# STM32G544 register map
File version: 2.0.0
CPU: CM33 r0p4, little endian, MPU, FPU, 4 interrupt priority bits
Registers are 32-bit, read-write, reset 0x0 unless marked. A register's access mark holds for its fields unless they carry their own. Offsets are from the block's base; [hi:lo] are bit positions; {n}, {i} and the like mark numbered series; 'fields as' and 'values as' point back to an identical list.

## GPDMA1 — GPDMA register block
Base 0x40020000
Same registers: GPDMA2 0x40021000, GPDMA1_S 0x50020000, GPDMA2_S 0x50021000
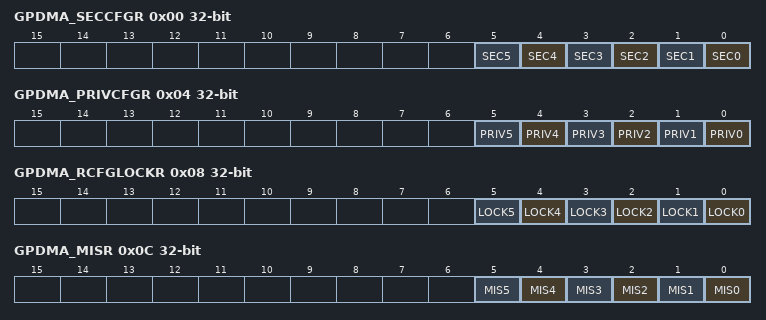
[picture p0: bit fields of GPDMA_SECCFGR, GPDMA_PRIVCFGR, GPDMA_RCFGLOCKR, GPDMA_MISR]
0x00 GPDMA_SECCFGR — GPDMA secure configuration register
  [all] fields
    0=Nonsecure; 1=Secure
  [n] SEC{n} (n=0..5) — secure state of channel x
0x04 GPDMA_PRIVCFGR — GPDMA privileged configuration register
  [all] fields
    0=unprivileged; 1=privileged
  [n] PRIV{n} (n=0..5) — privileged state of channel x
0x08 GPDMA_RCFGLOCKR — GPDMA configuration lock register
  [all] fields
    0=secure privilege configuration of the channel x is writable; 1=secure privilege configuration of the channel x is not writable
  [n] LOCK{n} (n=0..5) — lock the configuration of GPDMA_SECCFGR.
0x0C GPDMA_MISR ro — GPDMA nonsecure masked interrupt status register
  [all] fields
    0=no interrupt occurred on channel x; 1=an interrupt occurred on channel x
  [n] MIS{n} (n=0..5) — masked interrupt status of channel x
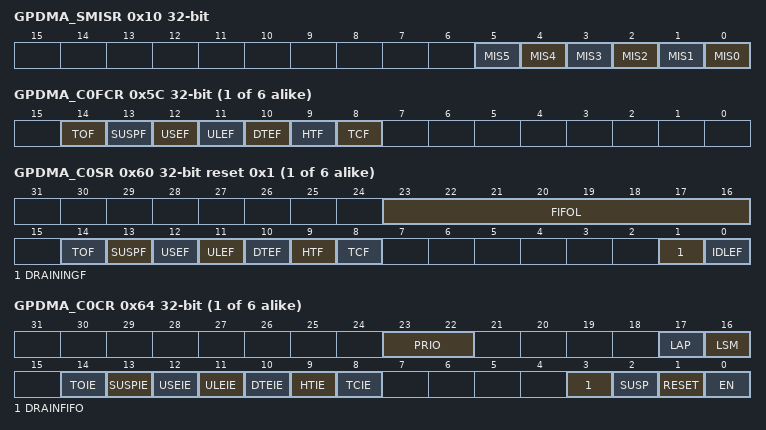
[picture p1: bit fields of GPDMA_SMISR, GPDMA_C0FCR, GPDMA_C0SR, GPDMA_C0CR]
0x10 GPDMA_SMISR ro — GPDMA secure masked interrupt status register
  [all] fields
    0=no interrupt occurred on the secure channel x; 1=an interrupt occurred on the secure channel x
  [n] MIS{n} (n=0..5) — masked interrupt status of the secure channel x
{0x50+0x80*i} GPDMA_C{i}LBAR (i=0..5) — GPDMA channel {i} linked-list base address register
  [31:16] LBA — linked-list base address of GPDMA channel x
{0x5C+0x80*i} GPDMA_C{i}FCR wo (i=0..5) — GPDMA channel {i} flag clear register
  [14] TOF — trigger overrun flag clear
    0=no effect; 1=corresponding TOF flag cleared
  [13] SUSPF — completed suspension flag clear
    0=no effect; 1=corresponding SUSPF flag cleared
  [12] USEF — user setting error flag clear
    0=no effect; 1=corresponding USEF flag cleared
  [11] ULEF — update link transfer error flag clear
    0=no effect; 1=corresponding ULEF flag cleared
  [10] DTEF — data transfer error flag clear
    0=no effect; 1=corresponding DTEF flag cleared
  [9] HTF — half transfer flag clear
    0=no effect; 1=corresponding HTF flag cleared
  [8] TCF — transfer complete flag clear
    0=no effect; 1=corresponding TCF flag cleared
{0x60+0x80*i} GPDMA_C{i}SR ro reset 0x1 (i=0..5) — GPDMA channel {i} status register
  [23:16] FIFOL — monitored FIFO level (in bytes)
  [14] TOF — trigger overrun flag
    0=no trigger overrun event; 1=a trigger overrun event occurred
  [13] SUSPF — completed suspension flag
    0=no completed suspension event; 1=a completed suspension event occurred
  [12] USEF — user setting error flag
    0=no user setting error event; 1=a user setting error event occurred
  [11] ULEF — update link transfer error flag
    0=no update link transfer error event; 1=a master bus error event occurred while updating a linked-list register from memory
  [10] DTEF — data transfer error flag
    0=no data transfer error event; 1=a master bus error event occurred on a data transfer
  [9] HTF — half transfer flag
    0=no half transfer event; 1=a half transfer event occurred
  [8] TCF — transfer complete flag
    0=no transfer complete event; 1=a transfer complete event occurred
  [1] DRAININGF — FIFO draining flag
    0=No received order to drain the FIFO or channel FIFO draining completed; 1=Ongoing channel FIFO draining and channel termination
  [0] IDLEF — idle flag
    0=channel not in idle state; 1=channel in idle state
{0x64+0x80*i} GPDMA_C{i}CR (i=0..5) — GPDMA channel {i} control register
  [23:22] PRIO — priority level of the channel x GPDMA transfer versus others
    0=low priority, low weight; 1=low priority, mid weight; 2=low priority, high weight; 3=high priority
  [17] LAP — linked-list allocated port
    0=port 0 (AHB) allocated; 1=port 1 (AHB) allocated
  [16] LSM — Link step mode
    0=channel executed for the full linked-list and completed at the end of the last LLI (GPDMA_CxLLR = 0); 1=channel executed once for the current LLI
  [14] TOIE — trigger overrun interrupt enable
    0=interrupt disabled; 1=interrupt enabled
  [13] SUSPIE — completed suspension interrupt enable
    0=interrupt disabled; 1=interrupt enabled
  [12] USEIE — user setting error interrupt enable
    0=interrupt disabled; 1=interrupt enabled
  [11] ULEIE — update link transfer error interrupt enable
    0=interrupt disabled; 1=interrupt enabled
  [10] DTEIE — data transfer error interrupt enable
    0=interrupt disabled; 1=interrupt enabled
  [9] HTIE — half transfer complete interrupt enable
    0=interrupt disabled; 1=interrupt enabled
  [8] TCIE — transfer complete interrupt enable
    0=interrupt disabled; 1=interrupt enabled
  [3] DRAINFIFO wo — empty FIFO
    0=Write: no action; 1=Write: drain FIFO after having suspended the channel
  [2] SUSP — suspend
    0=write: resume channel, read: channel not suspended; 1=write: suspend channel, read: channel suspended
  [1] RESET wo
    0=no channel reset; 1=channel reset
  [0] EN — enable
    0=write: ignored, read: channel disabled; 1=write: enable channel, read: channel enabled
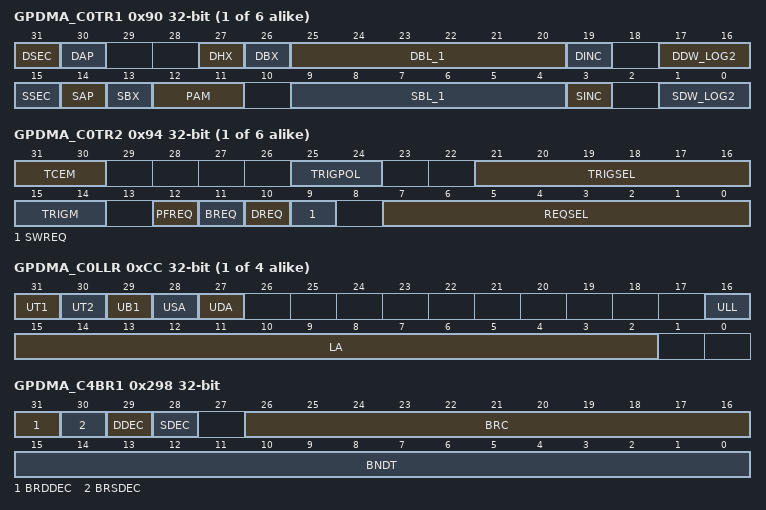
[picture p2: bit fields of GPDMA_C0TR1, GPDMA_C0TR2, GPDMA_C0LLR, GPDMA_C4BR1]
{0x90+0x80*i} GPDMA_C{i}TR1 (i=0..5) — GPDMA channel {i} transfer register 1
  [31] DSEC — security attribute of the GPDMA transfer to the destination
    0=GPDMA transfer nonsecure; 1=GPDMA transfer secure
  [30] DAP — destination allocated port
    0=port 0 (AHB) allocated; 1=port 1 (AHB) allocated
  [27] DHX — destination half-word exchange
    0=no halfword-based exchanged within word; 1=the two consecutive (post PAM) half-words are exchanged in each destination word
  [26] DBX — destination byte exchange
    0=no byte-based exchange within half-word; 1=the two consecutive (post PAM) bytes are exchanged in each destination half-word
  [25:20] DBL_1 — destination burst length minus 1, between 0 and 63
  [19] DINC — destination incrementing burst
    0=fixed burst; 1=contiguously incremented burst
  [17:16] DDW_LOG2 — binary logarithm of the destination data width of a burst, in bytes
    0=byte; 1=half-word (2 bytes); 2=word (4 bytes); 3=user setting error reported and no transfer issued
  [15] SSEC — security attribute of the GPDMA transfer from the source
    0=GPDMA transfer nonsecure; 1=GPDMA transfer secure
  [14] SAP — source allocated port
    0=port 0 (AHB) allocated; 1=port 1 (AHB) allocated
  [13] SBX — source byte exchange within the unaligned half-word of each source word
    0=no byte-based exchange within the unaligned half-word of each source word; 1=the two consecutive bytes within the unaligned half-word of each source word are exchanged
  [12:11] PAM — padding/alignment mode
    0=B_0x0_PAM_1 (source data is transferred as right aligned, padded with 0s up to the destination data width); 1=B_0x1_PAM_1 (source data is transferred as right aligned, sign extended up to the destination data width); 2=B_0x2_PAM_1 (successive source data are FIFO queued and packed at the destination data width, in a left (LSB) to right (MSB) order (named little endian), before a destination transfer); 3=B_0x3_PAM_1 (successive source data are FIFO queued and packed at the destination data width, in a left (LSB) to right (MSB) order (named little endian), before a destination transfer)
  [9:4] SBL_1 — source burst length minus 1, between 0 and 63
  [3] SINC — source incrementing burst
    0=fixed burst; 1=contiguously incremented burst
  [1:0] SDW_LOG2 — binary logarithm of the source data width of a burst in bytes
    values as DDW_LOG2
{0x94+0x80*i} GPDMA_C{i}TR2 (i=0..5) — GPDMA channel {i} transfer register 2
  [31:30] TCEM — transfer complete event mode
    0=at block level (when GPDMA_CxBR1; 1=channel x (x = 0 to 3), same as 00, channel x (x = 4 to 5), at 2D/repeated block level (when GPDMA_CxBR1; 2=at LLI level: the complete transfer event is generated at the end of the LLI transfer, including the update of the LLI if any; 3=at channel level: the complete transfer event is generated at the end of the last LLI transfer
  [25:24] TRIGPOL — trigger event polarity
    0=no trigger (masked trigger event); 1=trigger on the rising edge; 2=trigger on the falling edge; 3=same as 00
  [21:16] TRIGSEL — trigger event input selection
  [15:14] TRIGM — trigger mode
    0=at block level: the first burst read of each block transfer is conditioned by one hit trigger (channel x (x = 4 to 5), for each block if a 2D/repeated block is configured with GPDMA_CxBR1; 1=channel x (x = 0 to 3), same as 00; channel x (x = 4 to 5), at 2D/repeated block level; 2=at link level: a LLI link transfer is conditioned by one hit trigger; 3=at programmed burst level: If SWREQ=1, each programmed burst read is conditioned by one hit trigger
  [12] PFREQ — Hardware request in peripheral flow control mode
    0=the selected hardware request is driven by a peripheral with a hardware request/acknowledge protocol in GPDMA control mode; 1=the selected hardware request is driven by a peripheral with a hardware request/acknowledge protocol in peripheral control mode
  [11] BREQ — Block hardware request
    0=the selected hardware request is driven by a peripheral with a hardware request/acknowledge protocol at a burst level; 1=the selected hardware request is driven by a peripheral with a hardware request/acknowledge protocol at a block level (see Section17
  [10] DREQ — destination hardware request
    0=selected hardware request driven by a source peripheral (request signal taken into account by the GPDMA transfer scheduler over the source/read port); 1=selected hardware request driven by a destination peripheral (request signal taken into account by the GPDMA transfer scheduler over the destination/write port)
  [9] SWREQ — software request
    0=no software request; 1=software request for a memory-to-memory transfer
  [7:0] REQSEL — GPDMA hardware request selection
{0x98+0x80*i} GPDMA_C{i}BR1 (i=0..3) — GPDMA channel {i} block register 1
  [15:0] BNDT — block number of data bytes to transfer from the source
{0x9C+0x80*i} GPDMA_C{i}SAR (i=0..5) — GPDMA channel {i} source address register
  [31:0] SA — source address
{0xA0+0x80*i} GPDMA_C{i}DAR (i=0..5) — GPDMA channel {i} destination address register
  [31:0] DA — destination address
{0xCC+0x80*i} GPDMA_C{i}LLR (i=0..3) — GPDMA channel {i} linked-list address register
  [31] UT1 — Update GPDMA_CxTR1 from memory
    0=no GPDMA_CxTR1 update; 1=GPDMA_CxTR1 update
  [30] UT2 — Update GPDMA_CxTR2 from memory
    0=no GPDMA_CxTR2 update; 1=GPDMA_CxTR2 update
  [29] UB1 — Update GPDMA_CxBR1 from memory
    0=no GPDMA_CxBR1 update from memory (GPDMA_CxBR1; 1=GPDMA_CxBR1 update
  [28] USA — update GPDMA_CxSAR from memory
    0=no GPDMA_CxSAR update; 1=GPDMA_CxSAR update
  [27] UDA — Update GPDMA_CxDAR register from memory
    0=no GPDMA_CxDAR update; 1=GPDMA_CxDAR update
  [16] ULL — Update GPDMA_CxLLR register from memory
    0=no GPDMA_CxLLR update; 1=GPDMA_CxLLR update
  [15:2] LA — pointer (16-bit low-significant address) to the next linked-list data structure
0x298 GPDMA_C4BR1 — GPDMA channel 4 alternate block register 1
  [31] BRDDEC — Block repeat destination address decrement
    0=at the end of a block transfer, the GPDMA_CxDAR register is updated by adding the programmed offset GPDMA_CxBR2; 1=at the end of a block transfer, the GPDMA_CxDAR register is updated by subtracting the programmed offset GPDMA_CxBR2
  [30] BRSDEC — Block repeat source address decrement
    0=at the end of a block transfer, the GPDMA_CxSAR register is updated by adding the programmed offset GPDMA_CxBR2; 1=at the end of a block transfer, the GPDMA_CxSAR register is updated by subtracting the programmed offset GPDMA_CxBR2
  [29] DDEC — destination address decrement
    0=At the end of a programmed burst transfer to the destination, the GPDMA_CxDAR register is updated by adding the programmed offset GPDMA_CxTR3; 1=At the end of a programmed burst transfer to the destination, the GPDMA_CxDAR register is updated by subtracting the programmed offset GPDMA_CxTR3
  [28] SDEC — source address decrement
    0=At the end of a programmed burst transfer from the source, the GPDMA_CxSAR register is updated by adding the programmed offset GPDMA_CxTR3; 1=At the end of a programmed burst transfer from the source, the GPDMA_CxSAR register is updated by subtracting the programmed offset GPDMA_CxTR3
  [26:16] BRC — Block repeat counter
  [15:0] BNDT — block number of data bytes to transfer from the source
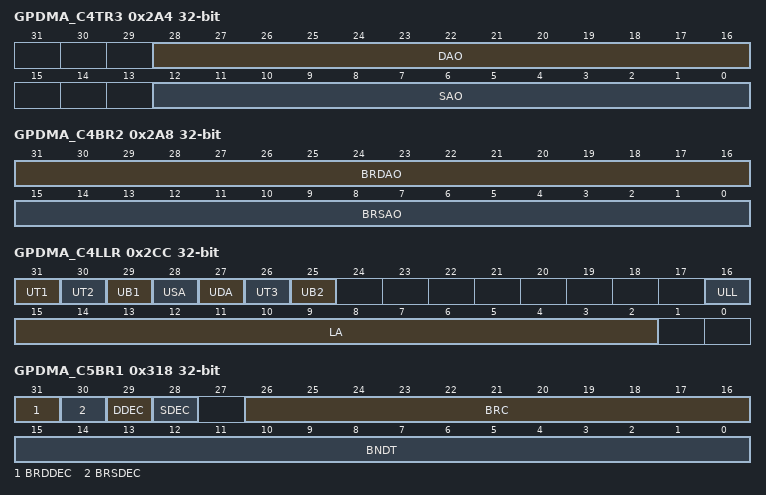
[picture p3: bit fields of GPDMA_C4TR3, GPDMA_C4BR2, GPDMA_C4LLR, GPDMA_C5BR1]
0x2A4 GPDMA_C4TR3 — GPDMA channel 4 transfer register 3
  [28:16] DAO — destination address offset increment
  [12:0] SAO — source address offset increment
0x2A8 GPDMA_C4BR2 — GPDMA channel 4 block register 2
  [31:16] BRDAO — Block repeated destination address offset
  [15:0] BRSAO — Block repeated source address offset
0x2CC GPDMA_C4LLR — GPDMA channel 4 alternate linked-list address register
  [31] UT1 — Update GPDMA_CxTR1 from memory
    0=no GPDMA_CxTR1 update; 1=GPDMA_CxTR1 update
  [30] UT2 — Update GPDMA_CxTR2 from memory
    0=no GPDMA_CxTR2 update; 1=GPDMA_CxTR2 update
  [29] UB1 — Update GPDMA_CxBR1 from memory
    values as GPDMA_C0LLR.UB1
  [28] USA — update GPDMA_CxSAR from memory
    0=no GPDMA_CxSAR update; 1=GPDMA_CxSAR update
  [27] UDA — Update GPDMA_CxDAR register from memory
    0=no GPDMA_CxDAR update; 1=GPDMA_CxDAR update
  [26] UT3 — Update GPDMA_CxTR3 from memory
    0=no GPDMA_CxTR3 update; 1=GPDMA_CxTR3 update
  [25] UB2 — Update GPDMA_CxBR2 from memory
    0=no GPDMA_CxBR2 update; 1=GPDMA_CxBR2 update
  [16] ULL — Update GPDMA_CxLLR register from memory
    0=no GPDMA_CxLLR update; 1=GPDMA_CxLLR update
  [15:2] LA — pointer (16-bit low-significant address) to the next linked-list data structure
0x318 GPDMA_C5BR1 — GPDMA channel 5 alternate block register 1
  fields as GPDMA_C4BR1
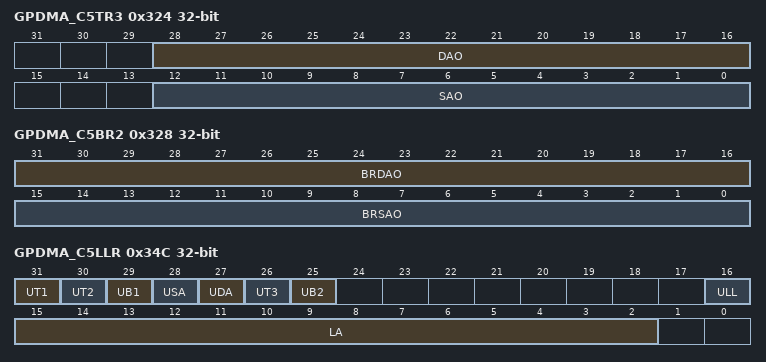
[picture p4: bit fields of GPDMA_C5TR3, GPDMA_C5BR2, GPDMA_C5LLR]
0x324 GPDMA_C5TR3 — GPDMA channel 5 transfer register 3
  fields as GPDMA_C4TR3
0x328 GPDMA_C5BR2 — GPDMA channel 5 block register 2
  fields as GPDMA_C4BR2
0x34C GPDMA_C5LLR — GPDMA channel 5 alternate linked-list address register
  fields as GPDMA_C4LLR
